VERSION ""

NS_ :

BS_:

BU_: DBG MASTER MOTOR SENSORS GEO BT

BO_ 80 STOP_CMD: 1 MASTER
 SG_ HALT : 0|1@1+ (1,0) [0|0] "" BT,SENSORS,MOTOR,GEO

BO_ 81 START_CMD: 1 MASTER
 SG_ INIT : 0|1@1+ (1,0) [0|0] "" BT,SENSORS,MOTOR,GEO

BO_ 82 MASTER_ACK_TO_BT_START: 1 MASTER
 SG_ ACK : 0|1@1+ (1,0) [0|0] "" BT

BO_ 83 BT_START_CMD: 1 BT
 SG_ BT_READY : 0|1@1+ (1,0) [0|0] "" MASTER

BO_ 84 BT_STOP_CMD: 1 BT
 SG_ BT_ABORT : 0|1@1+ (1,0) [0|0] "" MASTER

BO_ 95 HB_SENSORS: 1 SENSORS
 SG_ SENSOR_ALIVE : 0|1@1+ (1,0) [0|0] "HB-S" MASTER,MOTOR,GEO,BT

BO_ 96 HB_MOTORS: 1 MOTOR
 SG_ MOTOR_ALIVE : 0|1@1+ (1,0) [0|0] "HB-M" MASTER,SENSORS,GEO,BT

BO_ 97 HB_GEO: 1 GEO
 SG_ GEO_ALIVE : 0|1@1+ (1,0) [0|0] "HB-G" MASTER,SENSORS,MOTOR,BT

BO_ 98 HB_BT: 1 BT
 SG_ BT_ALIVE : 0|1@1+ (1,0) [0|0] "HB-BT" MASTER,SENSORS,MOTOR,GEO

BO_ 99 HB_MASTER: 1 MASTER
 SG_ MASTER_ALIVE : 0|1@1+ (1,0) [0|0] "HB-MT" BT,SENSORS,MOTOR,GEO

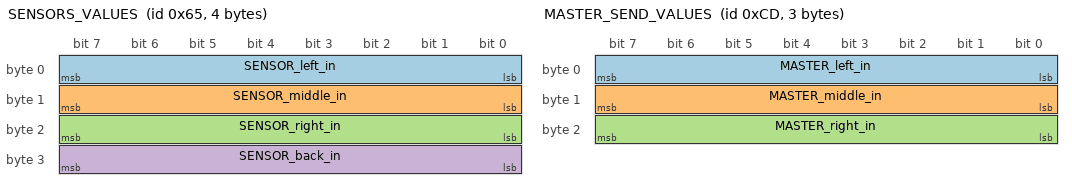
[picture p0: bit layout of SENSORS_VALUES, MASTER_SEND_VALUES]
BO_ 101 SENSORS_VALUES: 4 SENSORS
 SG_ SENSOR_left_in : 0|8@1+ (1,0) [0|0] "Inches" MASTER
 SG_ SENSOR_middle_in : 8|8@1+ (1,0) [0|0] "Inches" MASTER
 SG_ SENSOR_right_in : 16|8@1+ (1,0) [0|0] "Inches" MASTER
 SG_ SENSOR_back_in : 24|8@1+ (1,0) [0|0] "Inches" MASTER

BO_ 203 MASTER_SPEED: 2 MASTER
 SG_ MASTER_Maintain_Speed : 0|8@1+ (1,0) [0|30] "mph" MOTOR
 SG_ MASTER_Maintain_Direction : 8|8@1+ (1,0) [0|12] "" MOTOR

BO_ 205 MASTER_SEND_VALUES: 3 MASTER
 SG_ MASTER_left_in : 0|8@1+ (1,0) [0|0] "Inches" SENSORS
 SG_ MASTER_middle_in : 8|8@1+ (1,0) [0|0] "Inches" SENSORS
 SG_ MASTER_right_in : 16|8@1+ (1,0) [0|0] "Inches" SENSORS

BO_ 207 TRANSMIT_COORDINATES: 8 MASTER
 SG_ SET_LATTITUDE : 0|30@1+ (0.000001,-180) [-180|180] "DEGREE" MOTOR
 SG_ SET_LONGITUDE : 30|30@1+ (0.000001,-180) [-180|180] "DEGREE" MOTOR

BO_ 301 MOTOR_STATUS: 3 MOTOR
 SG_ MOTOR_Send_Speed : 0|8@1+ (0.1,0) [0|0] "mph" MASTER, BT
 SG_ MOTOR_Send_PWM : 8|12@1+ (0.01,0) [0|0] "PWM" MASTER, BT

BO_ 400 SEND_COORDINATES: 8 GEO
 SG_ SEND_LATTITUDE : 0|30@1+ (0.000001,-180) [-180|180] "DEGREE" MASTER
 SG_ SEND_LONGITUDE : 30|30@1+ (0.000001,-180) [-180|180] "DEGREE" MASTER

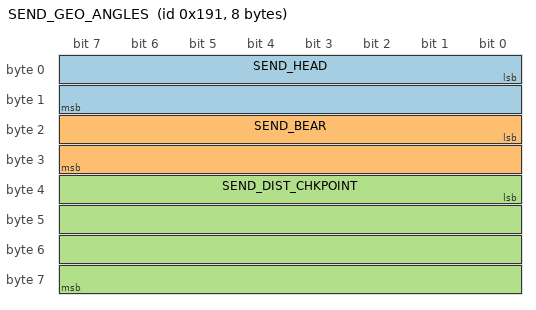
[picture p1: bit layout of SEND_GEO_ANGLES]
BO_ 401 SEND_GEO_ANGLES: 8 GEO
 SG_ SEND_HEAD : 0|16@1+ (1,0) [0|360] "DEGREE" MASTER,BT
 SG_ SEND_BEAR : 16|16@1- (1,0) [-180|180] "DEGREE" MASTER
 SG_ SEND_DIST_CHKPOINT : 32|32@1- (1,0) [0|0] "cm" MASTER

BO_ 406 SEND_GEO_READY: 1 GEO
 SG_ SAT_LOCK : 0|8@1+ (1,0) [0|0] "" MASTER,BT

BO_ 404 ALL_CHECKPOINTS_RECEIVED: 1 GEO
 SG_ GEO_CHECKPOINTS_READY : 0|8@1+ (1,0) [0|0] "" BT

BO_ 405 DESTINATION_REACHED: 1 GEO
 SG_ GEO_DESTINATION : 0|8@1+ (1,0) [0|0] "" MASTER

BO_ 407 SEND_CURRENT_COORDINATES: 8 GEO
 SG_ SEND_CURRENT_LATTITUDE : 0|30@1+ (0.000001,-180) [-180|180] "DEGREE" BT
 SG_ SEND_CURRENT_LONGITUDE : 30|30@1+ (0.000001,-180) [-180|180] "DEGREE" BT

BO_ 500 GET_START_COORDINATES: 1 BT
 SG_ GET_COORDINATES : 0|4@1+ (1,0) [0|0] "" MASTER, GEO

BO_ 503 SEND_ROUTE_COORDINATES: 8 BT
 SG_ SET_LATTITUDE : 0|30@1+ (0.000001,-180) [-180|180] "DEGREE" MASTER,GEO
 SG_ SET_LONGITUDE : 30|30@1+ (0.000001,-180) [-180|180] "DEGREE" MASTER,GEO

BO_ 504 SEND_NO_OF_CHECKPOINTS: 1 BT
 SG_ BT_NO_OF_COR : 0|8@1+ (1,0) [0|0] "" MASTER,GEO

BO_ 505 CHECKPOINTS_SENT: 1 BT
 SG_ BT_CHECKPOINTS_DONE : 0|8@1+ (1,0) [0|0] "" MASTER,GEO
